# nrf7120E_enga_application register map
Vendor: Nordic Semiconductor; Series: nrf71; File version: 1
CPU: CM33 r0p4, little endian, MPU, FPU, 3 interrupt priority bits, 270 interrupts, 4 SAU regions
Registers are 32-bit, read-write, reset 0x0 unless marked. A register's access mark holds for its fields unless they carry their own. Offsets are from the block's base; [hi:lo] are bit positions; lines under a group give offsets from that group; {n}, {i} and the like mark numbered series; 'fields as' and 'values as' point back to an identical list.

## GLOBAL_TWIS20_NS — I2C compatible Two-Wire Slave Interface with EasyDMA 0
Base 0x400C6000; alternate view of GLOBAL_SPIM20_NS
Same registers: GLOBAL_TWIS21_NS 0x400C7000 (alternate view of GLOBAL_SPIM21_NS), GLOBAL_TWIS22_NS 0x400C8000 (alternate view of GLOBAL_SPIM22_NS), GLOBAL_TWIS23_NS 0x400ED000 (alternate view of GLOBAL_SPIM23_NS), GLOBAL_TWIS24_NS 0x400EE000 (alternate view of GLOBAL_SPIM24_NS), GLOBAL_TWIS30_NS 0x40104000 (alternate view of GLOBAL_SPIM30_NS), GLOBAL_TWIS20_S 0x500C6000 (alternate view of GLOBAL_SPIM20_S), GLOBAL_TWIS21_S 0x500C7000 (alternate view of GLOBAL_SPIM21_S), GLOBAL_TWIS22_S 0x500C8000 (alternate view of GLOBAL_SPIM22_S), GLOBAL_TWIS23_S 0x500ED000 (alternate view of GLOBAL_SPIM23_S), GLOBAL_TWIS24_S 0x500EE000 (alternate view of GLOBAL_SPIM24_S), GLOBAL_TWIS30_S 0x50104000 (alternate view of GLOBAL_SPIM30_S)
0x04 TASKS_STOP wo — Stop TWI transaction
  [0] TASKS_STOP
    1=Trigger task
0x0C TASKS_SUSPEND wo — Suspend TWI transaction
  [0] TASKS_SUSPEND
    1=Trigger task
0x10 TASKS_RESUME wo — Resume TWI transaction
  [0] TASKS_RESUME
    1=Trigger task
0x20 TASKS_PREPARERX wo — Prepare the TWI slave to respond to a write command
  [0] TASKS_PREPARERX
    1=Trigger task
0x24 TASKS_PREPARETX wo — Prepare the TWI slave to respond to a read command
  [0] TASKS_PREPARETX
    1=Trigger task
0x30 TASKS_DMA group — Peripheral tasks.
  0x00 RX group — Peripheral tasks.
    {0x0+4k} ENABLEMATCH[{k}] (k=0..3) wo — Description collection: Enables the MATCH[n] event by setting the ENABLE[n] bit in the CONFIG register.
      [0] ENABLEMATCH — Enables the MATCH[n] event by setting the ENABLE[n] bit in the CONFIG register.
        1=Trigger task
    {0x10+4k} DISABLEMATCH[{k}] (k=0..3) wo — Description collection: Disables the MATCH[n] event by clearing the ENABLE[n] bit in the CONFIG register.
      [0] DISABLEMATCH — Disables the MATCH[n] event by clearing the ENABLE[n] bit in the CONFIG register.
        1=Trigger task
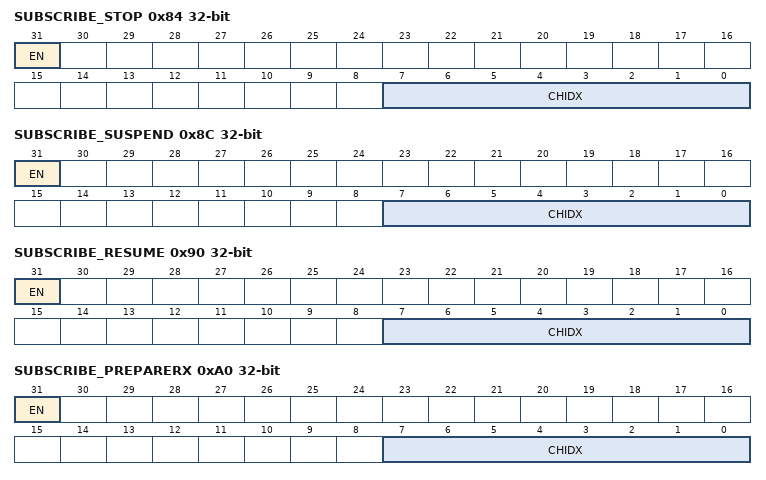
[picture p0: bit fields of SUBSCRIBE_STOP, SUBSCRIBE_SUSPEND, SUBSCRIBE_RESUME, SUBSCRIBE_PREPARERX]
0x84 SUBSCRIBE_STOP — Subscribe configuration for task STOP
  [31] EN
    0=Disabled (Disable subscription); 1=Enabled (Enable subscription)
  [7:0] CHIDX — DPPI channel that task STOP will subscribe to
0x8C SUBSCRIBE_SUSPEND — Subscribe configuration for task SUSPEND
  [31] EN
    values as SUBSCRIBE_STOP.EN
  [7:0] CHIDX — DPPI channel that task SUSPEND will subscribe to
0x90 SUBSCRIBE_RESUME — Subscribe configuration for task RESUME
  [31] EN
    values as SUBSCRIBE_STOP.EN
  [7:0] CHIDX — DPPI channel that task RESUME will subscribe to
0xA0 SUBSCRIBE_PREPARERX — Subscribe configuration for task PREPARERX
  [31] EN
    values as SUBSCRIBE_STOP.EN
  [7:0] CHIDX — DPPI channel that task PREPARERX will subscribe to
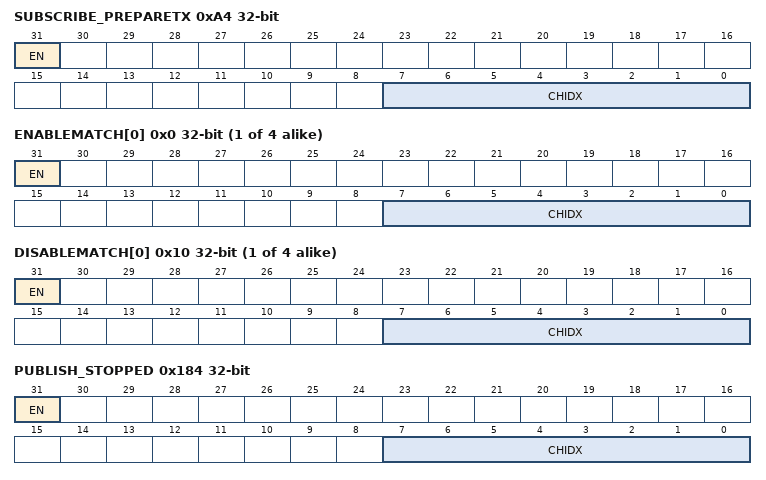
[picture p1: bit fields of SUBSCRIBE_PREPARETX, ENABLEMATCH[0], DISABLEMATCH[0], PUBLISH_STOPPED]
0xA4 SUBSCRIBE_PREPARETX — Subscribe configuration for task PREPARETX
  [31] EN
    values as SUBSCRIBE_STOP.EN
  [7:0] CHIDX — DPPI channel that task PREPARETX will subscribe to
0xB0 SUBSCRIBE_DMA group — Subscribe configuration for tasks
  0x00 RX group — Subscribe configuration for tasks
    {0x0+4k} ENABLEMATCH[{k}] (k=0..3) — Description collection: Subscribe configuration for task ENABLEMATCH[n]
      [31] EN
        values as SUBSCRIBE_STOP.EN
      [7:0] CHIDX — DPPI channel that task ENABLEMATCH[n] will subscribe to
    {0x10+4k} DISABLEMATCH[{k}] (k=0..3) — Description collection: Subscribe configuration for task DISABLEMATCH[n]
      [31] EN
        values as SUBSCRIBE_STOP.EN
      [7:0] CHIDX — DPPI channel that task DISABLEMATCH[n] will subscribe to
0x104 EVENTS_STOPPED — TWI stopped
  [0] EVENTS_STOPPED
    0=NotGenerated (Event not generated); 1=Generated (Event generated)
0x114 EVENTS_ERROR — TWI error
  [0] EVENTS_ERROR
    values as EVENTS_STOPPED.EVENTS_STOPPED
0x13C EVENTS_WRITE — Write command received
  [0] EVENTS_WRITE
    values as EVENTS_STOPPED.EVENTS_STOPPED
0x140 EVENTS_READ — Read command received
  [0] EVENTS_READ
    values as EVENTS_STOPPED.EVENTS_STOPPED
0x14C EVENTS_DMA group — Peripheral events.
  0x00 RX group — Peripheral events.
    0x00 END — Generated after EasyDMA has completed its operation.
      [0] END
        values as EVENTS_STOPPED.EVENTS_STOPPED
    0x04 READY — Generated when EasyDMA has buffered the .PTR and .MAXCNT registers for the channel, allowing them to be written to prepare for the next sequence.
      [0] READY
        values as EVENTS_STOPPED.EVENTS_STOPPED
    0x08 BUSERROR — An error occured during the bus transfer.
      [0] BUSERROR
        values as EVENTS_STOPPED.EVENTS_STOPPED
    {0xC+4k} MATCH[{k}] (k=0..3) — Description collection: Pattern match is detected on the DMA data bus.
      [0] MATCH — Pattern match is detected on the DMA data bus.
        values as EVENTS_STOPPED.EVENTS_STOPPED
  0x1C TX group — Peripheral events.
    0x00 END — Generated after EasyDMA has completed its operation.
      fields as EVENTS_DMA.RX.END
    0x04 READY — Generated when EasyDMA has buffered the .PTR and .MAXCNT registers for the channel, allowing them to be written to prepare for the next sequence.
      fields as EVENTS_DMA.RX.READY
    0x08 BUSERROR — An error occured during the bus transfer.
      fields as EVENTS_DMA.RX.BUSERROR
0x184 PUBLISH_STOPPED — Publish configuration for event STOPPED
  [31] EN
    0=Disabled (Disable publishing); 1=Enabled (Enable publishing)
  [7:0] CHIDX — DPPI channel that event STOPPED will publish to
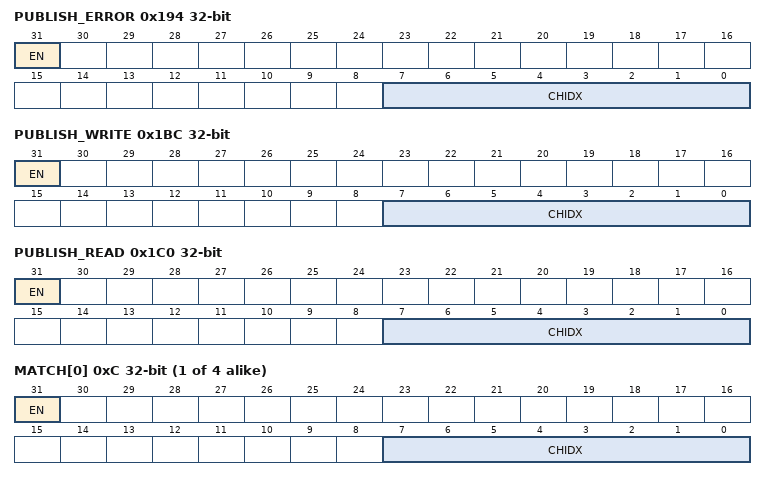
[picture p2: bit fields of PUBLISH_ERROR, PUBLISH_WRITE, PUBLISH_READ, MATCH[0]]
0x194 PUBLISH_ERROR — Publish configuration for event ERROR
  [31] EN
    values as PUBLISH_STOPPED.EN
  [7:0] CHIDX — DPPI channel that event ERROR will publish to
0x1BC PUBLISH_WRITE — Publish configuration for event WRITE
  [31] EN
    values as PUBLISH_STOPPED.EN
  [7:0] CHIDX — DPPI channel that event WRITE will publish to
0x1C0 PUBLISH_READ — Publish configuration for event READ
  [31] EN
    values as PUBLISH_STOPPED.EN
  [7:0] CHIDX — DPPI channel that event READ will publish to
0x1CC PUBLISH_DMA group — Publish configuration for events
  0x00 RX group — Publish configuration for events
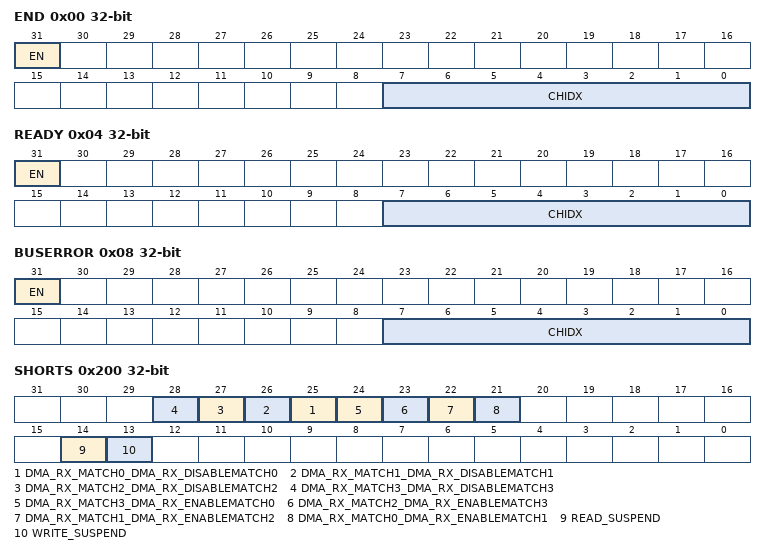
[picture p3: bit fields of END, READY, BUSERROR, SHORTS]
    0x00 END — Publish configuration for event END
      [31] EN
        values as PUBLISH_STOPPED.EN
      [7:0] CHIDX — DPPI channel that event END will publish to
    0x04 READY — Publish configuration for event READY
      [31] EN
        values as PUBLISH_STOPPED.EN
      [7:0] CHIDX — DPPI channel that event READY will publish to
    0x08 BUSERROR — Publish configuration for event BUSERROR
      [31] EN
        values as PUBLISH_STOPPED.EN
      [7:0] CHIDX — DPPI channel that event BUSERROR will publish to
    {0xC+4k} MATCH[{k}] (k=0..3) — Description collection: Publish configuration for event MATCH[n]
      [31] EN
        values as PUBLISH_STOPPED.EN
      [7:0] CHIDX — DPPI channel that event MATCH[n] will publish to
  0x1C TX group — Publish configuration for events
    0x00 END — Publish configuration for event END
      fields as PUBLISH_DMA.RX.END
    0x04 READY — Publish configuration for event READY
      fields as PUBLISH_DMA.RX.READY
    0x08 BUSERROR — Publish configuration for event BUSERROR
      fields as PUBLISH_DMA.RX.BUSERROR
0x200 SHORTS — Shortcuts between local events and tasks
  [all] fields
    0=Disabled (Disable shortcut); 1=Enabled (Enable shortcut)
  [n+25] DMA_RX_MATCH{n}_DMA_RX_DISABLEMATCH{n} (n=0..3) — Shortcut between event DMA.RX.MATCH[n] and task DMA.RX.DISABLEMATCH[n]
  [24] DMA_RX_MATCH3_DMA_RX_ENABLEMATCH0 — Shortcut between event DMA.RX.MATCH[n] and task DMA.RX.ENABLEMATCH[0] Allows daisy-chaining match events.
  [23] DMA_RX_MATCH2_DMA_RX_ENABLEMATCH3 — Shortcut between event DMA.RX.MATCH[n] and task DMA.RX.ENABLEMATCH[3] Allows daisy-chaining match events.
  [22] DMA_RX_MATCH1_DMA_RX_ENABLEMATCH2 — Shortcut between event DMA.RX.MATCH[n] and task DMA.RX.ENABLEMATCH[2] Allows daisy-chaining match events.
  [21] DMA_RX_MATCH0_DMA_RX_ENABLEMATCH1 — Shortcut between event DMA.RX.MATCH[n] and task DMA.RX.ENABLEMATCH[1] Allows daisy-chaining match events.
  [14] READ_SUSPEND — Shortcut between event READ and task SUSPEND
  [13] WRITE_SUSPEND — Shortcut between event WRITE and task SUSPEND
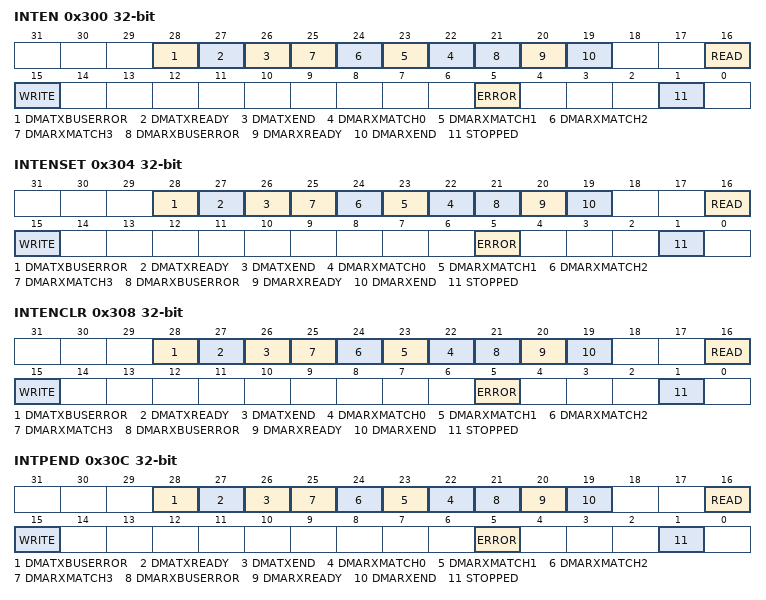
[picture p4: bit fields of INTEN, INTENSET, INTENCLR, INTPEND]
0x300 INTEN — Enable or disable interrupt
  [all] fields
    0=Disabled; 1=Enabled
  [28] DMATXBUSERROR — Enable or disable interrupt for event DMATXBUSERROR
  [27] DMATXREADY — Enable or disable interrupt for event DMATXREADY
  [26] DMATXEND — Enable or disable interrupt for event DMATXEND
  [n+22] DMARXMATCH{n} (n=0..3) — Enable or disable interrupt for event DMARXMATCH[{n}]
  [21] DMARXBUSERROR — Enable or disable interrupt for event DMARXBUSERROR
  [20] DMARXREADY — Enable or disable interrupt for event DMARXREADY
  [19] DMARXEND — Enable or disable interrupt for event DMARXEND
  [16] READ — Enable or disable interrupt for event READ
  [15] WRITE — Enable or disable interrupt for event WRITE
  [5] ERROR — Enable or disable interrupt for event ERROR
  [1] STOPPED — Enable or disable interrupt for event STOPPED
0x304 INTENSET — Enable interrupt
  [all] fields
    on read: 0=Disabled (Read: Disabled); 1=Enabled (Read: Enabled) | on write: 1=Set (Enable)
  [28] DMATXBUSERROR write-1-sets — Write '1' to enable interrupt for event DMATXBUSERROR
  [27] DMATXREADY write-1-sets — Write '1' to enable interrupt for event DMATXREADY
  [26] DMATXEND write-1-sets — Write '1' to enable interrupt for event DMATXEND
  [n+22] DMARXMATCH{n} write-1-sets (n=0..3) — Write '1' to enable interrupt for event DMARXMATCH[{n}]
  [21] DMARXBUSERROR write-1-sets — Write '1' to enable interrupt for event DMARXBUSERROR
  [20] DMARXREADY write-1-sets — Write '1' to enable interrupt for event DMARXREADY
  [19] DMARXEND write-1-sets — Write '1' to enable interrupt for event DMARXEND
  [16] READ write-1-sets — Write '1' to enable interrupt for event READ
  [15] WRITE write-1-sets — Write '1' to enable interrupt for event WRITE
  [5] ERROR write-1-sets — Write '1' to enable interrupt for event ERROR
  [1] STOPPED write-1-sets — Write '1' to enable interrupt for event STOPPED
0x308 INTENCLR — Disable interrupt
  [all] fields
    on read: 0=Disabled (Read: Disabled); 1=Enabled (Read: Enabled) | on write: 1=Clear (Disable)
  [28] DMATXBUSERROR write-1-clears — Write '1' to disable interrupt for event DMATXBUSERROR
  [27] DMATXREADY write-1-clears — Write '1' to disable interrupt for event DMATXREADY
  [26] DMATXEND write-1-clears — Write '1' to disable interrupt for event DMATXEND
  [n+22] DMARXMATCH{n} write-1-clears (n=0..3) — Write '1' to disable interrupt for event DMARXMATCH[{n}]
  [21] DMARXBUSERROR write-1-clears — Write '1' to disable interrupt for event DMARXBUSERROR
  [20] DMARXREADY write-1-clears — Write '1' to disable interrupt for event DMARXREADY
  [19] DMARXEND write-1-clears — Write '1' to disable interrupt for event DMARXEND
  [16] READ write-1-clears — Write '1' to disable interrupt for event READ
  [15] WRITE write-1-clears — Write '1' to disable interrupt for event WRITE
  [5] ERROR write-1-clears — Write '1' to disable interrupt for event ERROR
  [1] STOPPED write-1-clears — Write '1' to disable interrupt for event STOPPED
0x30C INTPEND ro — Pending interrupts
  [all] fields
    on read: 0=NotPending (Read: Not pending); 1=Pending (Read: Pending)
  [28] DMATXBUSERROR — Read pending status of interrupt for event DMATXBUSERROR
  [27] DMATXREADY — Read pending status of interrupt for event DMATXREADY
  [26] DMATXEND — Read pending status of interrupt for event DMATXEND
  [n+22] DMARXMATCH{n} (n=0..3) — Read pending status of interrupt for event DMARXMATCH[{n}]
  [21] DMARXBUSERROR — Read pending status of interrupt for event DMARXBUSERROR
  [20] DMARXREADY — Read pending status of interrupt for event DMARXREADY
  [19] DMARXEND — Read pending status of interrupt for event DMARXEND
  [16] READ — Read pending status of interrupt for event READ
  [15] WRITE — Read pending status of interrupt for event WRITE
  [5] ERROR — Read pending status of interrupt for event ERROR
  [1] STOPPED — Read pending status of interrupt for event STOPPED
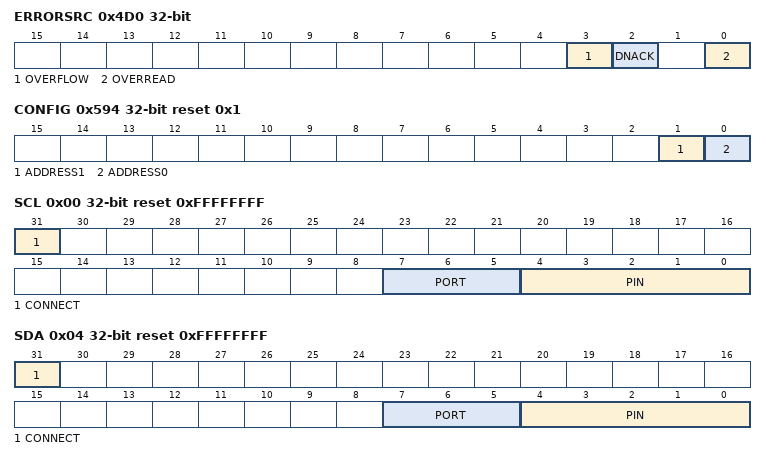
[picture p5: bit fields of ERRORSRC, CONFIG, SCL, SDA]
0x4D0 ERRORSRC write-1-clears — Error source
  [3] OVERFLOW — RX buffer overflow detected, and prevented
    0=NotDetected (Error did not occur); 1=Detected (Error occurred)
  [2] DNACK — NACK sent after receiving a data byte
    0=NotReceived (Error did not occur); 1=Received (Error occurred)
  [0] OVERREAD — TX buffer over-read detected, and prevented
    values as OVERFLOW
0x4D4 MATCH ro — Status register indicating which address had a match
  [0] MATCH — Indication of which address in ADDRESS that matched the incoming address
0x500 ENABLE — Enable TWIS
  [3:0] ENABLE — Enable or disable TWIS
    0=Disabled (Disable TWIS); 9=Enabled (Enable TWIS)
{0x588+4i} ADDRESS[{i}] (i=0..1) — Description collection: TWI slave address n
  [6:0] ADDRESS — TWI slave address
0x594 CONFIG reset 0x1 — Configuration register for the address match mechanism
  [1] ADDRESS1 — Enable or disable address matching on ADDRESS[1]
    0=Disabled; 1=Enabled
  [0] ADDRESS0 — Enable or disable address matching on ADDRESS[0]
    0=Disabled; 1=Enabled
0x5C0 ORC — Over-read character. Character sent out in case of an over-read of the transmit buffer.
  [7:0] ORC
0x600 PSEL group — Unspecified
  0x00 SCL reset 0xFFFFFFFF — Pin select for SCL signal
    [31] CONNECT — Connection
      1=Disconnected; 0=Connected
    [7:5] PORT — Port number
    [4:0] PIN — Pin number
  0x04 SDA reset 0xFFFFFFFF — Pin select for SDA signal
    fields as PSEL.SCL
0x700 DMA group — Unspecified
  0x00 RX group — Unspecified
    0x04 PTR reset 0x20000000 — RAM buffer start address
      [31:0] PTR — RAM buffer start address for this EasyDMA channel. This address is a word aligned Data RAM address.
    0x08 MAXCNT — Maximum number of bytes in channel buffer
      [15:0] MAXCNT
    0x0C AMOUNT ro — Number of bytes transferred in the last transaction, updated after the END event. For channels that supports the compare match filter, this register is also updated after each MATCH event.
      [15:0] AMOUNT — Number of bytes transferred in the last transaction. In case of NACK error, includes the NACK'ed byte.
    0x14 LIST — EasyDMA list type
      [2:0] TYPE — List type
        0=Disabled (Disable EasyDMA list); 1=ArrayList (Use array list)
    0x1C TERMINATEONBUSERROR — Terminate the transaction if a BUSERROR event is detected.
      [0] ENABLE
        0=Disabled; 1=Enabled
    0x20 BUSERRORADDRESS ro — Address of transaction that generated the last BUSERROR event.
      [31:0] ADDRESS
    0x24 MATCH group — Registers to control the behavior of the pattern matcher engine
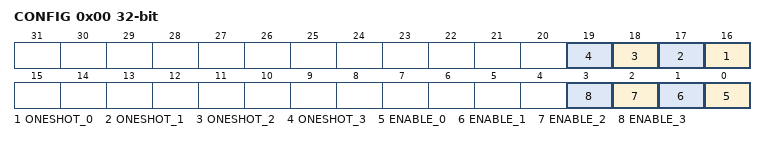
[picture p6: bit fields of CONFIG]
      0x00 CONFIG — Configure individual match events
        [n+16] ONESHOT_{n} (n=0..3) — Configure match filter {n} as one-shot or continous
          0=Continuous (Match filter stays enabled until disabled by task); 1=Oneshot (Match filter stays enabled until next data word is received)
        [n] ENABLE_{n} (n=0..3) — Enable match filter {n}
          0=Disabled (Match filter disabled); 1=Enabled (Match filter enabled)
      {0x4+4l} CANDIDATE[{l}] (l=0..3) — Description collection: The data to look for - any match will trigger the MATCH[n] event, if enabled.
        [7:0] DATA — Data to look for
  0x38 TX group — Unspecified
    0x04 PTR reset 0x20000000 — RAM buffer start address
      fields as DMA.RX.PTR
    0x08 MAXCNT — Maximum number of bytes in channel buffer
      [15:0] MAXCNT
    0x0C AMOUNT ro — Number of bytes transferred in the last transaction, updated after the END event. For channels that supports the compare match filter, this register is also updated after each MATCH event.
      fields as DMA.RX.AMOUNT
    0x14 LIST — EasyDMA list type
      fields as DMA.RX.LIST
    0x1C TERMINATEONBUSERROR — Terminate the transaction if a BUSERROR event is detected.
      [0] ENABLE
        0=Disabled; 1=Enabled
    0x20 BUSERRORADDRESS ro — Address of transaction that generated the last BUSERROR event.
      [31:0] ADDRESS
